# VIP1_VPDMA register map
Vendor: Texas Instruments
Registers are 32-bit, access per field, reset 0x0 unless marked. A register's access mark holds for its fields unless they carry their own. Offsets are as the file gives them; [hi:lo] are bit positions; {n}, {i} and the like mark numbered series.

## VIP1_VPDMA (part 3 of 5)
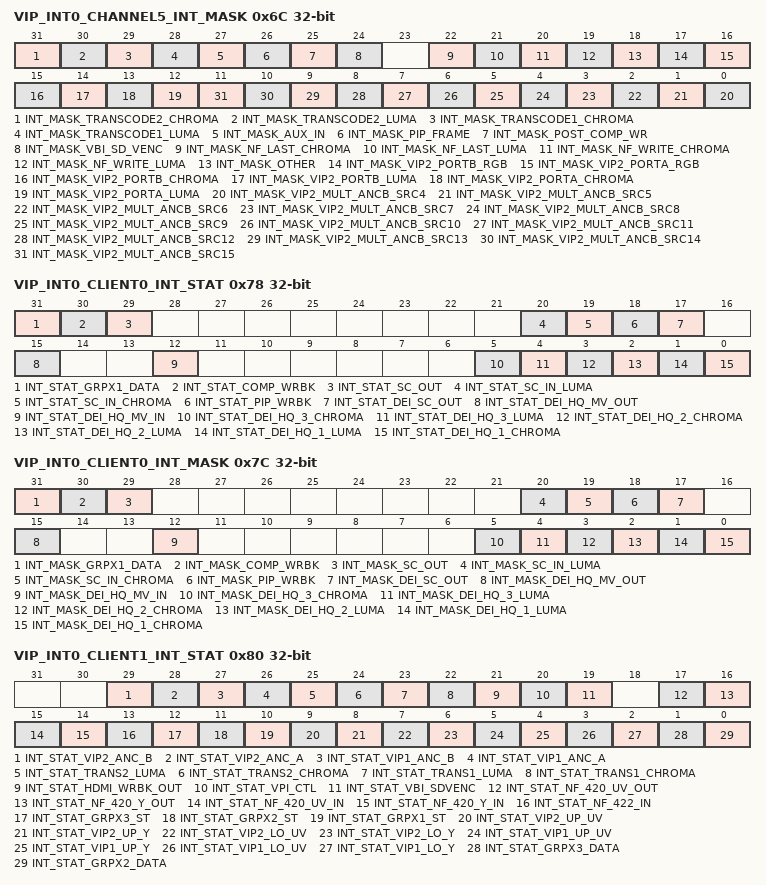
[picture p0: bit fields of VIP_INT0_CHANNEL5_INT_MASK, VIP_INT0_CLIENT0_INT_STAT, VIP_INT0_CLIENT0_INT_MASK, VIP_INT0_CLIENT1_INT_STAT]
0x6C VIP_INT0_CHANNEL5_INT_MASK — The register gives the information of the interrupts that should be masked and not generate an interrupt for vpdma_int0.
  [31] INT_MASK_TRANSCODE2_CHROMA rw — The interrupt for should generate an interrupt on interrupt vpdma_int0. Write a 1 for the interrupt event to trigger the interrupt signal.
  [30] INT_MASK_TRANSCODE2_LUMA rw — The interrupt for should generate an interrupt on interrupt vpdma_int0. Write a 1 for the interrupt event to trigger the interrupt signal.
  [29] INT_MASK_TRANSCODE1_CHROMA rw — The interrupt for should generate an interrupt on interrupt vpdma_int0. Write a 1 for the interrupt event to trigger the interrupt signal.
  [28] INT_MASK_TRANSCODE1_LUMA rw — The interrupt for should generate an interrupt on interrupt vpdma_int0. Write a 1 for the interrupt event to trigger the interrupt signal.
  [27] INT_MASK_AUX_IN rw — The interrupt for Auxilary Data for the Compositor Frame From Memory should generate an interrupt on interrupt vpdma_int0. Write a 1 for the interrupt event to trigger the interrupt signal.
  [26] INT_MASK_PIP_FRAME rw — The interrupt for PIP Data for the Compositor Frame From Memory should generate an interrupt on interrupt vpdma_int0. Write a 1 for the interrupt event to trigger the interrupt signal.
  [25] INT_MASK_POST_COMP_WR rw — The interrupt for Post Compositer Writeback to Memory should generate an interrupt on interrupt vpdma_int0. Write a 1 for the interrupt event to trigger the interrupt signal.
  [24] INT_MASK_VBI_SD_VENC rw — The interrupt for SD Video Encoder VBI Data should generate an interrupt on interrupt vpdma_int0. Write a 1 for the interrupt event to trigger the interrupt signal.
  [22] INT_MASK_NF_LAST_CHROMA rw — The interrupt for should generate an interrupt on interrupt vpdma_int0. Write a 1 for the interrupt event to trigger the interrupt signal.
  [21] INT_MASK_NF_LAST_LUMA rw — The interrupt for should generate an interrupt on interrupt vpdma_int0. Write a 1 for the interrupt event to trigger the interrupt signal.
  [20] INT_MASK_NF_WRITE_CHROMA rw — The interrupt for should generate an interrupt on interrupt vpdma_int0. Write a 1 for the interrupt event to trigger the interrupt signal.
  [19] INT_MASK_NF_WRITE_LUMA rw — The interrupt for should generate an interrupt on interrupt vpdma_int0. Write a 1 for the interrupt event to trigger the interrupt signal.
  [18] INT_MASK_OTHER rw — The interrupt for should generate an interrupt on interrupt vpdma_int0. Write a 1 for the interrupt event to trigger the interrupt signal.
  [17] INT_MASK_VIP2_PORTB_RGB rw — The interrupt for Video Input 2 Port B RGB Data should generate an interrupt on interrupt vpdma_int0. Write a 1 for the interrupt event to trigger the interrupt signal.
  [16] INT_MASK_VIP2_PORTA_RGB rw — The interrupt for Video Input 2 Port A RGB Data should generate an interrupt on interrupt vpdma_int0. Write a 1 for the interrupt event to trigger the interrupt signal.
  [15] INT_MASK_VIP2_PORTB_CHROMA rw — The interrupt for should generate an interrupt on interrupt vpdma_int0. Write a 1 for the interrupt event to trigger the interrupt signal.
  [14] INT_MASK_VIP2_PORTB_LUMA rw — The interrupt for should generate an interrupt on interrupt vpdma_int0. Write a 1 for the interrupt event to trigger the interrupt signal.
  [13] INT_MASK_VIP2_PORTA_CHROMA rw — The interrupt for should generate an interrupt on interrupt vpdma_int0. Write a 1 for the interrupt event to trigger the interrupt signal.
  [12] INT_MASK_VIP2_PORTA_LUMA rw — The interrupt for should generate an interrupt on interrupt vpdma_int0. Write a 1 for the interrupt event to trigger the interrupt signal.
  [n-4] INT_MASK_VIP2_MULT_ANCB_SRC{n} rw (n=4..15) — The interrupt for Video Input 2 Port B Ancillary Data Channel {n} should generate an interrupt on interrupt vpdma_int0. Write a 1 for the interrupt event to trigger the interrupt signal.
0x78 VIP_INT0_CLIENT0_INT_STAT — This register gives the information of the interrupts that have triggered since last cleared by the process that is servicing vpdma_int0.
  [31] INT_STAT_GRPX1_DATA rw — The client interface grpx1_data has reached its current configured interrupt event as specified by the last received control descriptor for this client. If no control descriptor has been configured this will default to having sent the End of Frame signal to the receiving module. This event will cause a one to be set in this register until cleared by software. Write a 1 to this field to clear the value.
  [30] INT_STAT_COMP_WRBK rw — The client interface comp_wrbk has reached its current configured interrupt event as specified by the last received control descriptor for this client. If no control descriptor has been configured this will default to having sent the End of Frame signal to the receiving module. This event will cause a one to be set in this register until cleared by software. Write a 1 to this field to clear the value.
  [29] INT_STAT_SC_OUT rw — The client interface sc_out has reached its current configured interrupt event as specified by the last received control descriptor for this client. If no control descriptor has been configured this will default to having received the End of Frame signal from the transmitting module. This event will cause a one to be set in this register until cleared by software. Write a 1 to this field to clear the value.
  [20] INT_STAT_SC_IN_LUMA rw — The client interface sc_in_luma has reached its current configured interrupt event as specified by the last received control descriptor for this client. If no control descriptor has been configured this will default to having sent the End of Frame signal to the receiving module. This event will cause a one to be set in this register until cleared by software. Write a 1 to this field to clear the value.
  [19] INT_STAT_SC_IN_CHROMA rw — The client interface sc_in_chroma has reached its current configured interrupt event as specified by the last received control descriptor for this client. If no control descriptor has been configured this will default to having sent the End of Frame signal to the receiving module. This event will cause a one to be set in this register until cleared by software. Write a 1 to this field to clear the value.
  [18] INT_STAT_PIP_WRBK rw — The client interface pip_wrbk has reached its current configured interrupt event as specified by the last received control descriptor for this client. If no control descriptor has been configured this will default to having sent the End of Frame signal to the receiving module. This event will cause a one to be set in this register until cleared by software. Write a 1 to this field to clear the value.
  [17] INT_STAT_DEI_SC_OUT rw — The client interface dei_sc_out has reached its current configured interrupt event as specified by the last received control descriptor for this client. If no control descriptor has been configured this will default to having received the End of Frame signal from the transmitting module. This event will cause a one to be set in this register until cleared by software. Write a 1 to this field to clear the value.
  [15] INT_STAT_DEI_HQ_MV_OUT rw — The client interface dei_hq_mv_out has reached its current configured interrupt event as specified by the last received control descriptor for this client. If no control descriptor has been configured this will default to having received the End of Frame signal from the transmitting module. This event will cause a one to be set in this register until cleared by software. Write a 1 to this field to clear the value.
  [12] INT_STAT_DEI_HQ_MV_IN rw — The client interface dei_hq_mv_in has reached its current configured interrupt event as specified by the last received control descriptor for this client. If no control descriptor has been configured this will default to having sent the End of Frame signal to the receiving module. This event will cause a one to be set in this register until cleared by software. Write a 1 to this field to clear the value.
  [5] INT_STAT_DEI_HQ_3_CHROMA rw — The client interface dei_hq_3_chroma has reached its current configured interrupt event as specified by the last received control descriptor for this client. If no control descriptor has been configured this will default to having sent the End of Frame signal to the receiving module. This event will cause a one to be set in this register until cleared by software. Write a 1 to this field to clear the value.
  [4] INT_STAT_DEI_HQ_3_LUMA rw — The client interface dei_hq_3_luma has reached its current configured interrupt event as specified by the last received control descriptor for this client. If no control descriptor has been configured this will default to having sent the End of Frame signal to the receiving module. This event will cause a one to be set in this register until cleared by software. Write a 1 to this field to clear the value.
  [3] INT_STAT_DEI_HQ_2_CHROMA rw — The client interface dei_hq_2_chroma has reached its current configured interrupt event as specified by the last received control descriptor for this client. If no control descriptor has been configured this will default to having sent the End of Frame signal to the receiving module. This event will cause a one to be set in this register until cleared by software. Write a 1 to this field to clear the value.
  [2] INT_STAT_DEI_HQ_2_LUMA rw — The client interface dei_hq_2_luma has reached its current configured interrupt event as specified by the last received control descriptor for this client. If no control descriptor has been configured this will default to having sent the End of Frame signal to the receiving module. This event will cause a one to be set in this register until cleared by software. Write a 1 to this field to clear the value.
  [1] INT_STAT_DEI_HQ_1_LUMA rw — The client interface dei_hq_1_luma has reached its current configured interrupt event as specified by the last received control descriptor for this client. If no control descriptor has been configured this will default to having sent the End of Frame signal to the receiving module. This event will cause a one to be set in this register until cleared by software. Write a 1 to this field to clear the value.
  [0] INT_STAT_DEI_HQ_1_CHROMA rw — The client interface dei_hq_1_chroma has reached its current configured interrupt event as specified by the last received control descriptor for this client. If no control descriptor has been configured this will default to having sent the End of Frame signal to the receiving module. This event will cause a one to be set in this register until cleared by software. Write a 1 to this field to clear the value.
0x7C VIP_INT0_CLIENT0_INT_MASK — The register gives the information of the interrupts that should be masked and not generate an interrupt for vpdma_int0.
  [31] INT_MASK_GRPX1_DATA rw — The interrupt for should generate an interrupt on interrupt vpdma_int0. Write a 1 for the interrupt event to trigger the interrupt signal.
  [30] INT_MASK_COMP_WRBK rw — The interrupt for should generate an interrupt on interrupt vpdma_int0. Write a 1 for the interrupt event to trigger the interrupt signal.
  [29] INT_MASK_SC_OUT rw — The interrupt for should generate an interrupt on interrupt vpdma_int0. Write a 1 for the interrupt event to trigger the interrupt signal.
  [20] INT_MASK_SC_IN_LUMA rw — The interrupt for should generate an interrupt on interrupt vpdma_int0. Write a 1 for the interrupt event to trigger the interrupt signal.
  [19] INT_MASK_SC_IN_CHROMA rw — The interrupt for should generate an interrupt on interrupt vpdma_int0. Write a 1 for the interrupt event to trigger the interrupt signal.
  [18] INT_MASK_PIP_WRBK rw — The interrupt for should generate an interrupt on interrupt vpdma_int0. Write a 1 for the interrupt event to trigger the interrupt signal.
  [17] INT_MASK_DEI_SC_OUT rw — The interrupt for should generate an interrupt on interrupt vpdma_int0. Write a 1 for the interrupt event to trigger the interrupt signal.
  [15] INT_MASK_DEI_HQ_MV_OUT rw — The interrupt for should generate an interrupt on interrupt vpdma_int0. Write a 1 for the interrupt event to trigger the interrupt signal.
  [12] INT_MASK_DEI_HQ_MV_IN rw — The interrupt for should generate an interrupt on interrupt vpdma_int0. Write a 1 for the interrupt event to trigger the interrupt signal.
  [5] INT_MASK_DEI_HQ_3_CHROMA rw — The interrupt for should generate an interrupt on interrupt vpdma_int0. Write a 1 for the interrupt event to trigger the interrupt signal.
  [4] INT_MASK_DEI_HQ_3_LUMA rw — The interrupt for should generate an interrupt on interrupt vpdma_int0. Write a 1 for the interrupt event to trigger the interrupt signal.
  [3] INT_MASK_DEI_HQ_2_CHROMA rw — The interrupt for should generate an interrupt on interrupt vpdma_int0. Write a 1 for the interrupt event to trigger the interrupt signal.
  [2] INT_MASK_DEI_HQ_2_LUMA rw — The interrupt for should generate an interrupt on interrupt vpdma_int0. Write a 1 for the interrupt event to trigger the interrupt signal.
  [1] INT_MASK_DEI_HQ_1_LUMA rw — The interrupt for should generate an interrupt on interrupt vpdma_int0. Write a 1 for the interrupt event to trigger the interrupt signal.
  [0] INT_MASK_DEI_HQ_1_CHROMA rw — The interrupt for should generate an interrupt on interrupt vpdma_int0. Write a 1 for the interrupt event to trigger the interrupt signal.
0x80 VIP_INT0_CLIENT1_INT_STAT access not given — This register gives the information of the interrupts that have triggered since last cleared by the process that is servicing vpdma_int0.
  [29] INT_STAT_VIP2_ANC_B — The client interface vip2_anc_b has reached its current configured interrupt event as specified by the last received control descriptor for this client. If no control descriptor has been configured this will default to having received the End of Frame signal from the transmitting module. This event will cause a one to be set in this register until cleared by software. Write a 1 to this field to clear the value. (access RW W0toClr)
  [28] INT_STAT_VIP2_ANC_A — The client interface vip2_anc_a has reached its current configured interrupt event as specified by the last received control descriptor for this client. If no control descriptor has been configured this will default to having received the End of Frame signal from the transmitting module. This event will cause a one to be set in this register until cleared by software. Write a 1 to this field to clear the value. (access RW W0toClr)
  [27] INT_STAT_VIP1_ANC_B — The client interface vip1_anc_b has reached its current configured interrupt event as specified by the last received control descriptor for this client. If no control descriptor has been configured this will default to having received the End of Frame signal from the transmitting module. This event will cause a one to be set in this register until cleared by software. Write a 1 to this field to clear the value. (access RW W0toClr)
  [26] INT_STAT_VIP1_ANC_A — The client interface vip1_anc_a has reached its current configured interrupt event as specified by the last received control descriptor for this client. If no control descriptor has been configured this will default to having received the End of Frame signal from the transmitting module. This event will cause a one to be set in this register until cleared by software. Write a 1 to this field to clear the value. (access RW W0toClr)
  [25] INT_STAT_TRANS2_LUMA — The client interface trans2_luma has reached its current configured interrupt event as specified by the last received control descriptor for this client. If no control descriptor has been configured this will default to having sent the End of Frame signal to the receiving module. This event will cause a one to be set in this register until cleared by software. Write a 1 to this field to clear the value. (access RW W0toClr)
  [24] INT_STAT_TRANS2_CHROMA — The client interface trans2_chroma has reached its current configured interrupt event as specified by the last received control descriptor for this client. If no control descriptor has been configured this will default to having sent the End of Frame signal to the receiving module. This event will cause a one to be set in this register until cleared by software. Write a 1 to this field to clear the value. (access RW W0toClr)
  [23] INT_STAT_TRANS1_LUMA — The client interface trans1_luma has reached its current configured interrupt event as specified by the last received control descriptor for this client. If no control descriptor has been configured this will default to having sent the End of Frame signal to the receiving module. This event will cause a one to be set in this register until cleared by software. Write a 1 to this field to clear the value. (access RW W0toClr)
  [22] INT_STAT_TRANS1_CHROMA — The client interface trans1_chroma has reached its current configured interrupt event as specified by the last received control descriptor for this client. If no control descriptor has been configured this will default to having sent the End of Frame signal to the receiving module. This event will cause a one to be set in this register until cleared by software. Write a 1 to this field to clear the value. (access RW W0toClr)
  [21] INT_STAT_HDMI_WRBK_OUT — The client interface hdmi_wrbk_out has reached its current configured interrupt event as specified by the last received control descriptor for this client. If no control descriptor has been configured this will default to having received the End of Frame signal from the transmitting module. This event will cause a one to be set in this register until cleared by software. Write a 1 to this field to clear the value. (access RW W0toClr)
  [20] INT_STAT_VPI_CTL — The client interface vpi_ctl has reached its current configured interrupt event as specified by the last received control descriptor for this client. If no control descriptor has been configured this will default to having sent the End of Frame signal to the receiving module. This event will cause a one to be set in this register until cleared by software. Write a 1 to this field to clear the value. (access RW W0toClr)
  [19] INT_STAT_VBI_SDVENC — The client interface vbi_sdvenc has reached its current configured interrupt event as specified by the last received control descriptor for this client. If no control descriptor has been configured this will default to having sent the End of Frame signal to the receiving module. This event will cause a one to be set in this register until cleared by software. Write a 1 to this field to clear the value. (access RW W0toClr)
  [17] INT_STAT_NF_420_UV_OUT — The client interface nf_420_uv_out has reached its current configured interrupt event as specified by the last received control descriptor for this client. If no control descriptor has been configured this will default to having received the End of Frame signal from the transmitting module. This event will cause a one to be set in this register until cleared by software. Write a 1 to this field to clear the value. (access RW W0toClr)
  [16] INT_STAT_NF_420_Y_OUT — The client interface nf_420_y_out has reached its current configured interrupt event as specified by the last received control descriptor for this client. If no control descriptor has been configured this will default to having received the End of Frame signal from the transmitting module. This event will cause a one to be set in this register until cleared by software. Write a 1 to this field to clear the value. (access RW W0toClr)
  [15] INT_STAT_NF_420_UV_IN — The client interface nf_420_uv_in has reached its current configured interrupt event as specified by the last received control descriptor for this client. If no control descriptor has been configured this will default to having sent the End of Frame signal to the receiving module. This event will cause a one to be set in this register until cleared by software. Write a 1 to this field to clear the value. (access RW W0toClr)
  [14] INT_STAT_NF_420_Y_IN — The client interface nf_420_y_in has reached its current configured interrupt event as specified by the last received control descriptor for this client. If no control descriptor has been configured this will default to having sent the End of Frame signal to the receiving module. This event will cause a one to be set in this register until cleared by software. Write a 1 to this field to clear the value. (access RW W0toClr)
  [13] INT_STAT_NF_422_IN — The client interface nf_422_in has reached its current configured interrupt event as specified by the last received control descriptor for this client. If no control descriptor has been configured this will default to having sent the End of Frame signal to the receiving module. This event will cause a one to be set in this register until cleared by software. Write a 1 to this field to clear the value. (access RW W0toClr)
  [12] INT_STAT_GRPX3_ST — The client interface grpx3_st has reached its current configured interrupt event as specified by the last received control descriptor for this client. If no control descriptor has been configured this will default to having sent the End of Frame signal to the receiving module. This event will cause a one to be set in this register until cleared by software. Write a 1 to this field to clear the value. (access RW W0toClr)
  [11] INT_STAT_GRPX2_ST — The client interface grpx2_st has reached its current configured interrupt event as specified by the last received control descriptor for this client. If no control descriptor has been configured this will default to having sent the End of Frame signal to the receiving module. This event will cause a one to be set in this register until cleared by software. Write a 1 to this field to clear the value. (access RW W0toClr)
  [10] INT_STAT_GRPX1_ST — The client interface grpx1_st has reached its current configured interrupt event as specified by the last received control descriptor for this client. If no control descriptor has been configured this will default to having sent the End of Frame signal to the receiving module. This event will cause a one to be set in this register until cleared by software. Write a 1 to this field to clear the value. (access RW W0toClr)
  [9] INT_STAT_VIP2_UP_UV — The client interface vip2_up_uv has reached its current configured interrupt event as specified by the last received control descriptor for this client. If no control descriptor has been configured this will default to having received the End of Frame signal from the transmitting module. This event will cause a one to be set in this register until cleared by software. Write a 1 to this field to clear the value. (access RW W0toClr)
  [8] INT_STAT_VIP2_UP_Y — The client interface vip2_up_y has reached its current configured interrupt event as specified by the last received control descriptor for this client. If no control descriptor has been configured this will default to having received the End of Frame signal from the transmitting module. This event will cause a one to be set in this register until cleared by software. Write a 1 to this field to clear the value. (access RW W0toClr)
  [7] INT_STAT_VIP2_LO_UV — The client interface vip2_lo_uv has reached its current configured interrupt event as specified by the last received control descriptor for this client. If no control descriptor has been configured this will default to having received the End of Frame signal from the transmitting module. This event will cause a one to be set in this register until cleared by software. Write a 1 to this field to clear the value. (access RW W0toClr)
  [6] INT_STAT_VIP2_LO_Y — The client interface vip2_lo_y has reached its current configured interrupt event as specified by the last received control descriptor for this client. If no control descriptor has been configured this will default to having received the End of Frame signal from the transmitting module. This event will cause a one to be set in this register until cleared by software. Write a 1 to this field to clear the value. (access RW W0toClr)
  [5] INT_STAT_VIP1_UP_UV — The client interface vip1_up_uv has reached its current configured interrupt event as specified by the last received control descriptor for this client. If no control descriptor has been configured this will default to having received the End of Frame signal from the transmitting module. This event will cause a one to be set in this register until cleared by software. Write a 1 to this field to clear the value. (access RW W0toClr)
  [4] INT_STAT_VIP1_UP_Y — The client interface vip1_up_y has reached its current configured interrupt event as specified by the last received control descriptor for this client. If no control descriptor has been configured this will default to having received the End of Frame signal from the transmitting module. This event will cause a one to be set in this register until cleared by software. Write a 1 to this field to clear the value. (access RW W0toClr)
  [3] INT_STAT_VIP1_LO_UV — The client interface vip1_lo_uv has reached its current configured interrupt event as specified by the last received control descriptor for this client. If no control descriptor has been configured this will default to having received the End of Frame signal from the transmitting module. This event will cause a one to be set in this register until cleared by software. Write a 1 to this field to clear the value. (access RW W0toClr)
  [2] INT_STAT_VIP1_LO_Y — The client interface vip1_lo_y has reached its current configured interrupt event as specified by the last received control descriptor for this client. If no control descriptor has been configured this will default to having received the End of Frame signal from the transmitting module. This event will cause a one to be set in this register until cleared by software. Write a 1 to this field to clear the value. (access RW W0toClr)
  [1] INT_STAT_GRPX3_DATA — The client interface grpx3_data has reached its current configured interrupt event as specified by the last received control descriptor for this client. If no control descriptor has been configured this will default to having sent the End of Frame signal to the receiving module. This event will cause a one to be set in this register until cleared by software. Write a 1 to this field to clear the value. (access RW W0toClr)
  [0] INT_STAT_GRPX2_DATA — The client interface grpx2_data has reached its current configured interrupt event as specified by the last received control descriptor for this client. If no control descriptor has been configured this will default to having sent the End of Frame signal to the receiving module. This event will cause a one to be set in this register until cleared by software. Write a 1 to this field to clear the value. (access RW W0toClr)
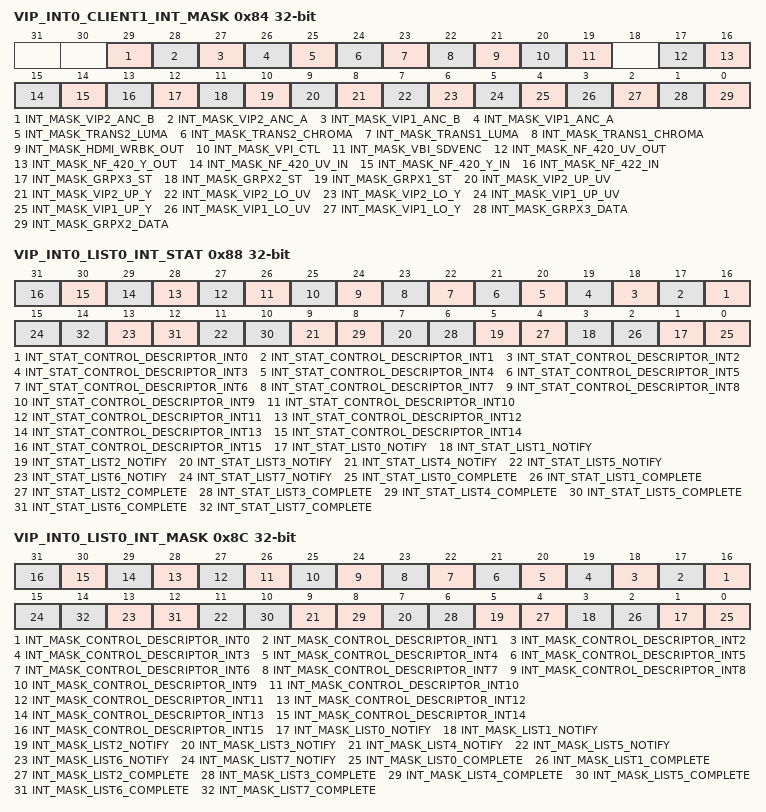
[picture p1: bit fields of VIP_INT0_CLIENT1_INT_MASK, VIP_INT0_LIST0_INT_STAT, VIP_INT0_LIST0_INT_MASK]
0x84 VIP_INT0_CLIENT1_INT_MASK — The register gives the information of the interrupts that should be masked and not generate an interrupt for vpdma_int0.
  [29] INT_MASK_VIP2_ANC_B rw — The interrupt for should generate an interrupt on interrupt vpdma_int0. Write a 1 for the interrupt event to trigger the interrupt signal.
  [28] INT_MASK_VIP2_ANC_A rw — The interrupt for should generate an interrupt on interrupt vpdma_int0. Write a 1 for the interrupt event to trigger the interrupt signal.
  [27] INT_MASK_VIP1_ANC_B rw — The interrupt for should generate an interrupt on interrupt vpdma_int0. Write a 1 for the interrupt event to trigger the interrupt signal.
  [26] INT_MASK_VIP1_ANC_A rw — The interrupt for should generate an interrupt on interrupt vpdma_int0. Write a 1 for the interrupt event to trigger the interrupt signal.
  [25] INT_MASK_TRANS2_LUMA rw — The interrupt for should generate an interrupt on interrupt vpdma_int0. Write a 1 for the interrupt event to trigger the interrupt signal.
  [24] INT_MASK_TRANS2_CHROMA rw — The interrupt for should generate an interrupt on interrupt vpdma_int0. Write a 1 for the interrupt event to trigger the interrupt signal.
  [23] INT_MASK_TRANS1_LUMA rw — The interrupt for should generate an interrupt on interrupt vpdma_int0. Write a 1 for the interrupt event to trigger the interrupt signal.
  [22] INT_MASK_TRANS1_CHROMA rw — The interrupt for should generate an interrupt on interrupt vpdma_int0. Write a 1 for the interrupt event to trigger the interrupt signal.
  [21] INT_MASK_HDMI_WRBK_OUT rw — The interrupt for should generate an interrupt on interrupt vpdma_int0. Write a 1 for the interrupt event to trigger the interrupt signal.
  [20] INT_MASK_VPI_CTL rw — The interrupt for should generate an interrupt on interrupt vpdma_int0. Write a 1 for the interrupt event to trigger the interrupt signal.
  [19] INT_MASK_VBI_SDVENC rw — The interrupt for should generate an interrupt on interrupt vpdma_int0. Write a 1 for the interrupt event to trigger the interrupt signal.
  [17] INT_MASK_NF_420_UV_OUT rw — The interrupt for should generate an interrupt on interrupt vpdma_int0. Write a 1 for the interrupt event to trigger the interrupt signal.
  [16] INT_MASK_NF_420_Y_OUT rw — The interrupt for should generate an interrupt on interrupt vpdma_int0. Write a 1 for the interrupt event to trigger the interrupt signal.
  [15] INT_MASK_NF_420_UV_IN rw — The interrupt for should generate an interrupt on interrupt vpdma_int0. Write a 1 for the interrupt event to trigger the interrupt signal.
  [14] INT_MASK_NF_420_Y_IN rw — The interrupt for should generate an interrupt on interrupt vpdma_int0. Write a 1 for the interrupt event to trigger the interrupt signal.
  [13] INT_MASK_NF_422_IN rw — The interrupt for should generate an interrupt on interrupt vpdma_int0. Write a 1 for the interrupt event to trigger the interrupt signal.
  [12] INT_MASK_GRPX3_ST rw — The interrupt for should generate an interrupt on interrupt vpdma_int0. Write a 1 for the interrupt event to trigger the interrupt signal.
  [11] INT_MASK_GRPX2_ST rw — The interrupt for should generate an interrupt on interrupt vpdma_int0. Write a 1 for the interrupt event to trigger the interrupt signal.
  [10] INT_MASK_GRPX1_ST rw — The interrupt for should generate an interrupt on interrupt vpdma_int0. Write a 1 for the interrupt event to trigger the interrupt signal.
  [9] INT_MASK_VIP2_UP_UV rw — The interrupt for should generate an interrupt on interrupt vpdma_int0. Write a 1 for the interrupt event to trigger the interrupt signal.
  [8] INT_MASK_VIP2_UP_Y rw — The interrupt for should generate an interrupt on interrupt vpdma_int0. Write a 1 for the interrupt event to trigger the interrupt signal.
  [7] INT_MASK_VIP2_LO_UV rw — The interrupt for should generate an interrupt on interrupt vpdma_int0. Write a 1 for the interrupt event to trigger the interrupt signal.
  [6] INT_MASK_VIP2_LO_Y rw — The interrupt for should generate an interrupt on interrupt vpdma_int0. Write a 1 for the interrupt event to trigger the interrupt signal.
  [5] INT_MASK_VIP1_UP_UV rw — The interrupt for should generate an interrupt on interrupt vpdma_int0. Write a 1 for the interrupt event to trigger the interrupt signal.
  [4] INT_MASK_VIP1_UP_Y rw — The interrupt for should generate an interrupt on interrupt vpdma_int0. Write a 1 for the interrupt event to trigger the interrupt signal.
  [3] INT_MASK_VIP1_LO_UV rw — The interrupt for should generate an interrupt on interrupt vpdma_int0. Write a 1 for the interrupt event to trigger the interrupt signal.
  [2] INT_MASK_VIP1_LO_Y rw — The interrupt for should generate an interrupt on interrupt vpdma_int0. Write a 1 for the interrupt event to trigger the interrupt signal.
  [1] INT_MASK_GRPX3_DATA rw — The interrupt for should generate an interrupt on interrupt vpdma_int0. Write a 1 for the interrupt event to trigger the interrupt signal.
  [0] INT_MASK_GRPX2_DATA rw — The interrupt for should generate an interrupt on interrupt vpdma_int0. Write a 1 for the interrupt event to trigger the interrupt signal.
0x88 VIP_INT0_LIST0_INT_STAT rw — This register gives the information of the interrupts that have triggered since last cleared by the process that is servicing vpdma_int0.
  [n+16] INT_STAT_CONTROL_DESCRIPTOR_INT{n} (n=0..15) — A Send Interrupt Control Descriptor has been received by the list manager with a source value of {n}. This event will cause a one to be set in this register until cleared by software. Write a 1 to this field to clear the value.
  [2n+1] INT_STAT_LIST{n}_NOTIFY (n=0..7) — A channel set by List {n} has completed and the Notify bit had been set in the descriptor for that channel. This event will cause a one to be set in this register until cleared by software. Write a 1 to this field to clear the value.
  [2n] INT_STAT_LIST{n}_COMPLETE (n=0..7) — List {n} has completed and a new list can be loaded. This event will cause a one to be set in this register until cleared by software. Write a 1 to this field to clear the value.
0x8C VIP_INT0_LIST0_INT_MASK rw — The register gives the information of the interrupts that should be masked and not generate an interrupt for vpdma_int0.
  [n+16] INT_MASK_CONTROL_DESCRIPTOR_INT{n} (n=0..15) — The interrupt for should generate an interrupt on interrupt vpdma_int0. Write a 1 for the interrupt event to trigger the interrupt signal.
  [2n+1] INT_MASK_LIST{n}_NOTIFY (n=0..7) — The interrupt for should generate an interrupt on interrupt vpdma_int0. Write a 1 for the interrupt event to trigger the interrupt signal.
  [2n] INT_MASK_LIST{n}_COMPLETE (n=0..7) — The interrupt for should generate an interrupt on interrupt vpdma_int0. Write a 1 for the interrupt event to trigger the interrupt signal.
